# OCP2SCP3 register map
Vendor: Texas Instruments
Peripheral module from a debugger description file (folder am572x).
Registers are 32-bit, read-only, reset 0x1 unless marked. A register's access mark holds for its fields unless they carry their own. Offsets are as the file gives them; lines under a group give offsets from that group; [hi:lo] are bit positions; {n}, {i} and the like mark numbered series; 'fields as' and 'values as' point back to an identical list; <NAME> marks a mode.

## OCP2SCP3
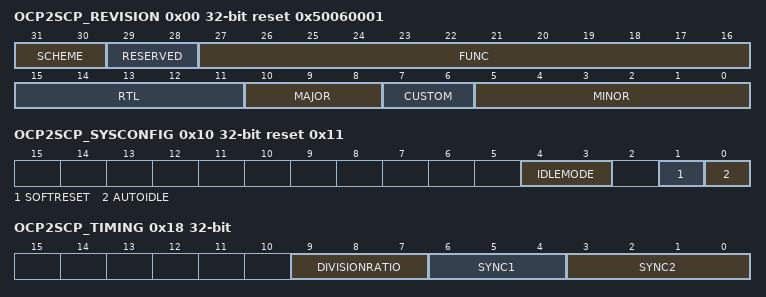
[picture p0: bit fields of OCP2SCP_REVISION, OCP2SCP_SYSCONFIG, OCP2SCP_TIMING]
0x00 OCP2SCP_REVISION reset 0x50060001 — IP Revision Identifier (X.Y.R)
  [31:30] SCHEME — Used to distinguish between old Scheme and current. Spare bit to encode future schemes.
  [29:28] RESERVED — Reads return 0x1
  [27:16] FUNC — Function: Indicates a software compatible module family
  [15:11] RTL — RTL version This field changes on bug fix, and resets to
  [10:8] MAJOR — ajor Revision This field changes when there is a major feature change. This field does not change due to bug fix, or minor feature change.
  [7:6] CUSTOM — Indicates a special version for a particular device. Consequence of use may avoid use of standard Chip Support Library (CSL)/Drivers. 0 if non-custom.
  [5:0] MINOR — inor Revision This field changes when features are scaled up or down. This field does not change due to bug fix, or major feature change.
0x10 OCP2SCP_SYSCONFIG access per field reset 0x11 — SYSTEM CONFIGURATION REGISTER
  [4:3] IDLEMODE rw
    0=Force Idle mode. An idle request is acknowledged unconditionally.; 1=No Idle mode. An idle request is never acknowledged.; 2=Reserved (Smart Idle mode. The acknowledgement to an idle request is given based on the internal activity.); 3=Smart Idle Wakeup
  [1] SOFTRESET rw — Software Reset. Set this bit to 1 to trigger a module reset. The bit is automatically reset by the hardware. During reads, it always returns 0.
    0=Normal Mode; 1=Reset (The module is reset.)
  [0] AUTOIDLE rw — OCP interface clock gating control.
    0=FreeRun (Internal OCP interface clock is free-running); 1=Automatic internal OCP interface clock gating, based on the OCP interface activity
0x14 OCP2SCP_SYSSTATUS — System Status register.
  [0] RESETDONE
    1=Complete (Reset completed); 0=InProgress (Internal Reset is on-going)
0x18 OCP2SCP_TIMING access per field — Interrupt Status Register (legacy) for first line of interrupt.
  [9:7] DIVISIONRATIO rw — Division Ration of the SCP clock in relation to OCP input clock.
  [6:4] SYNC1 rw — Number of SCPclock cycles defining SYNC1
  [3:0] SYNC2 rw — Number of SCPclock cycles defining SYNC2
